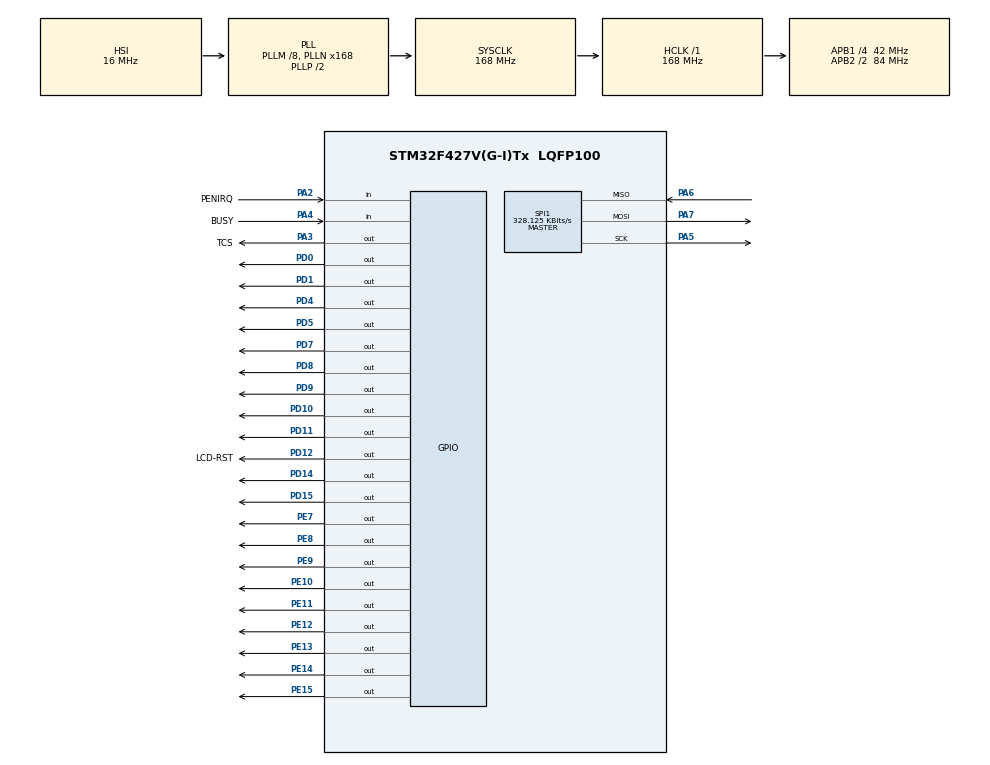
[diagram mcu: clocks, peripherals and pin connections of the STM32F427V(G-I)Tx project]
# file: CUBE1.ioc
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Mcu.Family=STM32F4
Mcu.Name=STM32F427V(G-I)Tx
Mcu.Package=LQFP100
NVIC.PriorityGroup=NVIC_PRIORITYGROUP_4
PA13.Mode=Serial_Wire
PA13.Signal=SYS_JTMS-SWDIO
PA14.Mode=Serial_Wire
PA14.Signal=SYS_JTCK-SWCLK
PA2.GPIO_Label=PENIRQ
PA2.GPIO_PuPd=GPIO_PULLUP
PA2.Signal=GPIO_Input
PA3.GPIO_Label=TCS
PA3.GPIO_PuPd=GPIO_PULLUP
PA3.GPIO_Speed=GPIO_SPEED_FREQ_HIGH
PA3.PinState=GPIO_PIN_SET
PA3.Signal=GPIO_Output
PA4.GPIO_Label=BUSY
PA4.GPIO_PuPd=GPIO_PULLUP
PA4.Signal=GPIO_Input
PA5.GPIO_PuPd=GPIO_PULLUP
PA5.GPIO_Speed=GPIO_SPEED_FREQ_HIGH
PA5.Mode=Full_Duplex_Master
PA5.Signal=SPI1_SCK
PA6.GPIO_PuPd=GPIO_PULLUP
PA6.GPIO_Speed=GPIO_SPEED_FREQ_HIGH
PA6.Mode=Full_Duplex_Master
PA6.Signal=SPI1_MISO
PA7.GPIO_PuPd=GPIO_PULLUP
PA7.GPIO_Speed=GPIO_SPEED_FREQ_HIGH
PA7.Mode=Full_Duplex_Master
PA7.Signal=SPI1_MOSI
PD0.GPIO_ModeDefaultOutputPP=GPIO_MODE_OUTPUT_PP
PD0.GPIO_PuPd=GPIO_PULLUP
PD0.GPIO_Speed=GPIO_SPEED_FREQ_HIGH
PD0.PinState=GPIO_PIN_SET
PD0.Signal=GPIO_Output
PD1.GPIO_ModeDefaultOutputPP=GPIO_MODE_OUTPUT_PP
PD1.GPIO_PuPd=GPIO_PULLUP
PD1.GPIO_Speed=GPIO_SPEED_FREQ_HIGH
PD1.PinState=GPIO_PIN_SET
PD1.Signal=GPIO_Output
PD10.GPIO_ModeDefaultOutputPP=GPIO_MODE_OUTPUT_PP
PD10.GPIO_PuPd=GPIO_PULLUP
PD10.GPIO_Speed=GPIO_SPEED_FREQ_HIGH
PD10.PinState=GPIO_PIN_SET
PD10.Signal=GPIO_Output
PD11.GPIO_ModeDefaultOutputPP=GPIO_MODE_OUTPUT_PP
PD11.GPIO_PuPd=GPIO_PULLUP
PD11.GPIO_Speed=GPIO_SPEED_FREQ_HIGH
PD11.PinState=GPIO_PIN_SET
PD11.Signal=GPIO_Output
PD12.GPIO_Label=LCD-RST
PD12.GPIO_ModeDefaultOutputPP=GPIO_MODE_OUTPUT_PP
PD12.GPIO_PuPd=GPIO_PULLUP
PD12.GPIO_Speed=GPIO_SPEED_FREQ_HIGH
PD12.PinState=GPIO_PIN_SET
PD12.Signal=GPIO_Output
PD14.GPIO_ModeDefaultOutputPP=GPIO_MODE_OUTPUT_PP
PD14.GPIO_PuPd=GPIO_PULLUP
PD14.GPIO_Speed=GPIO_SPEED_FREQ_HIGH
PD14.PinState=GPIO_PIN_SET
PD14.Signal=GPIO_Output
PD15.GPIO_ModeDefaultOutputPP=GPIO_MODE_OUTPUT_PP
PD15.GPIO_PuPd=GPIO_PULLUP
PD15.GPIO_Speed=GPIO_SPEED_FREQ_HIGH
PD15.PinState=GPIO_PIN_SET
PD15.Signal=GPIO_Output
PD4.GPIO_ModeDefaultOutputPP=GPIO_MODE_OUTPUT_PP
PD4.GPIO_PuPd=GPIO_PULLUP
PD4.GPIO_Speed=GPIO_SPEED_FREQ_HIGH
PD4.PinState=GPIO_PIN_SET
PD4.Signal=GPIO_Output
PD5.GPIO_ModeDefaultOutputPP=GPIO_MODE_OUTPUT_PP
PD5.GPIO_PuPd=GPIO_PULLUP
PD5.GPIO_Speed=GPIO_SPEED_FREQ_HIGH
PD5.PinState=GPIO_PIN_SET
PD5.Signal=GPIO_Output
PD7.GPIO_ModeDefaultOutputPP=GPIO_MODE_OUTPUT_PP
PD7.GPIO_PuPd=GPIO_PULLUP
PD7.GPIO_Speed=GPIO_SPEED_FREQ_HIGH
PD7.PinState=GPIO_PIN_SET
PD7.Signal=GPIO_Output
PD8.GPIO_ModeDefaultOutputPP=GPIO_MODE_OUTPUT_PP
PD8.GPIO_PuPd=GPIO_PULLUP
PD8.GPIO_Speed=GPIO_SPEED_FREQ_HIGH
PD8.PinState=GPIO_PIN_SET
PD8.Signal=GPIO_Output
PD9.GPIO_ModeDefaultOutputPP=GPIO_MODE_OUTPUT_PP
PD9.GPIO_PuPd=GPIO_PULLUP
PD9.GPIO_Speed=GPIO_SPEED_FREQ_HIGH
PD9.PinState=GPIO_PIN_SET
PD9.Signal=GPIO_Output
PE10.GPIO_ModeDefaultOutputPP=GPIO_MODE_OUTPUT_PP
PE10.GPIO_PuPd=GPIO_PULLUP
PE10.GPIO_Speed=GPIO_SPEED_FREQ_HIGH
PE10.PinState=GPIO_PIN_SET
PE10.Signal=GPIO_Output
PE11.GPIO_ModeDefaultOutputPP=GPIO_MODE_OUTPUT_PP
PE11.GPIO_PuPd=GPIO_PULLUP
PE11.GPIO_Speed=GPIO_SPEED_FREQ_HIGH
PE11.PinState=GPIO_PIN_SET
PE11.Signal=GPIO_Output
PE12.GPIO_ModeDefaultOutputPP=GPIO_MODE_OUTPUT_PP
PE12.GPIO_PuPd=GPIO_PULLUP
PE12.GPIO_Speed=GPIO_SPEED_FREQ_HIGH
PE12.PinState=GPIO_PIN_SET
PE12.Signal=GPIO_Output
PE13.GPIO_ModeDefaultOutputPP=GPIO_MODE_OUTPUT_PP
PE13.GPIO_PuPd=GPIO_PULLUP
PE13.GPIO_Speed=GPIO_SPEED_FREQ_HIGH
PE13.PinState=GPIO_PIN_SET
PE13.Signal=GPIO_Output
PE14.GPIO_ModeDefaultOutputPP=GPIO_MODE_OUTPUT_PP
PE14.GPIO_PuPd=GPIO_PULLUP
PE14.GPIO_Speed=GPIO_SPEED_FREQ_HIGH
PE14.PinState=GPIO_PIN_SET
PE14.Signal=GPIO_Output
PE15.GPIO_ModeDefaultOutputPP=GPIO_MODE_OUTPUT_PP
PE15.GPIO_PuPd=GPIO_PULLUP
PE15.GPIO_Speed=GPIO_SPEED_FREQ_HIGH
PE15.PinState=GPIO_PIN_SET
PE15.Signal=GPIO_Output
PE7.GPIO_ModeDefaultOutputPP=GPIO_MODE_OUTPUT_PP
PE7.GPIO_PuPd=GPIO_PULLUP
PE7.GPIO_Speed=GPIO_SPEED_FREQ_HIGH
PE7.PinState=GPIO_PIN_SET
PE7.Signal=GPIO_Output
PE8.GPIO_ModeDefaultOutputPP=GPIO_MODE_OUTPUT_PP
PE8.GPIO_PuPd=GPIO_PULLUP
PE8.GPIO_Speed=GPIO_SPEED_FREQ_HIGH
PE8.PinState=GPIO_PIN_SET
PE8.Signal=GPIO_Output
PE9.GPIO_ModeDefaultOutputPP=GPIO_MODE_OUTPUT_PP
PE9.GPIO_PuPd=GPIO_PULLUP
PE9.GPIO_Speed=GPIO_SPEED_FREQ_HIGH
PE9.PinState=GPIO_PIN_SET
PE9.Signal=GPIO_Output
ProjectManager.HeapSize=0x200
ProjectManager.StackSize=0x400
ProjectManager.TargetToolchain=Other Toolchains (GPDSC)
RCC.48MHZClocksFreq_Value=84000000
RCC.AHBFreq_Value=168000000
RCC.APB1CLKDivider=RCC_HCLK_DIV4
RCC.APB1Freq_Value=42000000
RCC.APB1TimFreq_Value=84000000
RCC.APB2CLKDivider=RCC_HCLK_DIV2
RCC.APB2Freq_Value=84000000
RCC.APB2TimFreq_Value=168000000
RCC.CortexFreq_Value=168000000
RCC.HCLKFreq_Value=168000000
RCC.HSE_VALUE=25000000
RCC.HSI_VALUE=16000000
RCC.LSE_VALUE=32768
RCC.PLLM=8
RCC.PLLN=168
RCC.SYSCLKFreq_VALUE=168000000
RCC.SYSCLKSource=RCC_SYSCLKSOURCE_PLLCLK
RCC.VCOOutputFreq_Value=336000000
SPI1.BaudRatePrescaler=SPI_BAUDRATEPRESCALER_256
SPI1.CLKPhase=SPI_PHASE_2EDGE
SPI1.CLKPolarity=SPI_POLARITY_HIGH
SPI1.CRCCalculation=SPI_CRCCALCULATION_DISABLE
SPI1.CalculateBaudRate=328.125 KBits/s
SPI1.DataSize=SPI_DATASIZE_8BIT
SPI1.Direction=SPI_DIRECTION_2LINES
SPI1.FirstBit=SPI_FIRSTBIT_MSB
SPI1.Mode=SPI_MODE_MASTER
SPI1.VirtualType=VM_MASTER
VP_CRC_VS_CRC.Mode=CRC_Activate
board=custom

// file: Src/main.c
/* USER CODE BEGIN Header */
/**
  ******************************************************************************
  * @file           : main.c
  * @brief          : Main program body
  ******************************************************************************
  * @attention
  *
  * <h2><center>&copy; Copyright (c) 2020 STMicroelectronics.
  * All rights reserved.</center></h2>
  *
  * This software component is licensed by ST under BSD 3-Clause license,
  * the "License"; You may not use this file except in compliance with the
  * License. You may obtain a copy of the License at:
  *                        opensource.org/licenses/BSD-3-Clause
  *
  ******************************************************************************
  */
/* USER CODE END Header */

#include "main.h"

/* USER CODE BEGIN Includes */
#include "GUI.h"
#include "HX8352B-F4-PAR.h"
#include "WindowDLG.h"
#include "GUITDRV_ADS7846.h"
#include "XPT2046-REZ.h"
/* USER CODE END Includes */

CRC_HandleTypeDef hcrc;

SPI_HandleTypeDef hspi1;

/* USER CODE BEGIN PV */
uint8_t		TDATA[3], BUSY, TCMD[6];
uint16_t	Result, TCSDATA[4];
/* USER CODE END PV */

void SystemClock_Config(void);
static void MX_GPIO_Init(void);
static void MX_CRC_Init(void);
static void MX_SPI1_Init(void);

int main(void)
{

  /* MCU Configuration--------------------------------------------------------*/

  /* Reset of all peripherals, Initializes the Flash interface and the Systick. */
  HAL_Init();

  /* Configure the system clock */
  SystemClock_Config();

  /* Initialize all configured peripherals */
  MX_GPIO_Init();
  MX_CRC_Init();
  MX_SPI1_Init();
  /* USER CODE BEGIN 2 */
	GUI_Init();
	//GUI_SetFont(&GUI_Font32B_1);
	//GUI_SetBkColor(GUI_BLUE);
	//GUI_SetColor(GUI_BLACK);
	//GUI_SetLineStyle(GUI_LS_DASHDOTDOT);
	//GUI_CURSOR_Select(&GUI_CursorArrowM);
	//GUI_CURSOR_SetPosition(10, 150);
	//GUI_Clear();
	//GUI_SetLineStyle(GUI_LS_SOLID);
	//LCD_RECT GUI_RECT = { 0 };
	//GUI_RECT.x0 = 70;
	//GUI_RECT.x1 = 350;
	//GUI_RECT.y0 = 70;
	//GUI_RECT.y1 = 160;

	//GUI_DrawRect(60, 60, 350, 160);

	//GUI_DispStringInRect("Hello.........World!", &GUI_RECT, GUI_TA_HCENTER);

	//GUI_CURSOR_SetPosition(20, 50);
	//GUI_CURSOR_Show();

	//
	MainTask();  // CreateWindow();

  /* USER CODE END 2 */

  /* Infinite loop */
  while(1)
	{

    /* USER CODE BEGIN 3 */

		//CreateWindow();
		HAL_Delay(100);

		/*

		SendCmd(0XD0);
		TCSDATA[3] = GetResult();
		SetCS(1);

		HAL_Delay(100);

			TOUCH_X_Init				// S / A2 A1 A0 / MODE / SER_DFR / PD1 PD0
		TCMD[0] = 0X90;   //1 / 101        / 1   / 0        / 00       X-POSITION
		TCMD[1] = 0X00;   //1 / 001        / 1   / 0        / 00       Y-POSITION
		TCMD[2] = 0X00;

		TCMD[3] = 0XD0;
		TCMD[4] = 0X00;
		TCMD[5] = 0X00;

		//YY :if (HAL_GPIO_ReadPin(GPIOA, PENIRQ_Pin)) {goto YY; }	else

		HAL_GPIO_WritePin(GPIOA, TCS_Pin, GPIO_PIN_RESET);
		HAL_Delay(1);

		HAL_SPI_TransmitReceive(&hspi1, &TCMD[0], &TDATA[0], 1, 15);
		HAL_SPI_TransmitReceive(&hspi1, &TCMD[1], &TDATA[1], 2, 15);
		TCSDATA[3] = ((TDATA[1] << 4) | (TDATA[2] >> 4)) & 0X0FFF;

		HAL_SPI_TransmitReceive(&hspi1, &TCMD[3], &TDATA[0], 1, 15);
		HAL_SPI_TransmitReceive(&hspi1, &TCMD[4], &TDATA[1], 2, 15);
		TCSDATA[2] = ((TDATA[1] << 4) | (TDATA[2] >> 4)) & 0X0FFF;

		HAL_GPIO_WritePin(GPIOA, TCS_Pin, GPIO_PIN_SET);

							// S / A2 A1 A0 / MODE / SER_DFR / PD1 PD0
		TCMD[0] = 0XD0;   //1 / 101        / 1   / 0        / 00       X-POSITION
		TCMD[1] = 0X90;   //1 / 001        / 1   / 0        / 00       Y-POSITION
		TCMD[2] = 0X00;

		HAL_SPI_TransmitReceive(&hspi1, &TCMD[0], &TDATA[0], 1, 5);
		HAL_SPI_TransmitReceive(&hspi1, &TCMD[2], &TDATA[1], 1, 5);
		TCSDATA[0] = TDATA[0];
		TCSDATA[1] = TDATA[1];
		TCSDATA[3] = ((TCSDATA[0] << 4) | (TCSDATA[1] >> 4)) & 0X0FFF;

		 	XX:
		if (HAL_GPIO_ReadPin(GPIOA, BUSY_Pin) == 0)
		{
			HAL_SPI_Receive(&hspi1, &TDATA[0], 1, 25);
			HAL_SPI_Receive(&hspi1, &TDATA[1], 1, 25);
			TCSDATA = (TDATA[0] << 4 | TDATA[1]>>4) & 0X0FFF;
		}
		else goto XX;

		HAL_SPI_Transmit(&hspi1, &TCMD[1], 1, 5);
		YY :
		if (HAL_GPIO_ReadPin(GPIOA, BUSY_Pin) == 0)
		{}		else goto YY;

			HAL_Delay(40);
		GUITDRV_ADS7846_Exec();
		HAL_Delay(40);

		 HAL_Delay(10);
		GUI_DispStringAt("Hello.........World!", 50, 10);
		HAL_Delay(10);
		GUI_DispStringAt("Hello.........World!", 50, 50);
		HAL_Delay(10);
		GUI_DispStringAt("Hello.........World!", 50, 100);
		HAL_Delay(10);
		GUI_DispStringAt("Hello.........World!!", 50, 150);
		HAL_Delay(10);
		GUI_DispStringAt("Hello.........World!!", 50, 200);
		HAL_Delay(10);
		GUI_Clear();
		HAL_Delay(10);
		//GUI_DrawRect(50, 50, 350, 160);
		//GUI_DispStringInRect("Hello.........World!", &GUI_RECT, GUI_TA_HCENTER);
		HAL_Delay(1000);
		GUI_Clear();

		 E1 = ((address << 3) & 0XFF80);
		 D1 = (address << 14) & 0XC000;
		 D2 = (address >> 2) & 0X0003;
		 D3 = (address >> 5) & 0X0700;
		 D4 = (D1 | D2 | D3) | 0X38FC;
		 GPIOE->ODR = E1;
		 GPIOD->ODR = D4;
		 HAL_Delay(20);
		 GPIOD->ODR = D4 & CS_MASK; 		//CS=LOW RS=HIGH WR=HIGH RD=HIGH
		 HAL_Delay(30);
		 GPIOD->ODR = D4 & (RS_MASK & CS_MASK);  		//CS=LOW RS=LOW WR=HIGH RD=HIGH
		 HAL_Delay(20);
		 GPIOD->ODR = D4 & (WR_MASK & RS_MASK & CS_MASK); 		//CS=LOW RS=LOW WR=LOW RD=HIGH
		 HAL_Delay(20);
		 GPIOD->ODR = (D4 & (RS_MASK & CS_MASK)) | (~WR_MASK);   	//CS=LOW RS=LOW WR=HIGH RD=HIGH
		 HAL_Delay(20);
		 GPIOD->ODR = (D4 & (CS_MASK)) | (~RS_MASK); 	//CS=LOW RS=HIGH WR=HIGH RD=HIGH
		 HAL_Delay(20);
		 */
	}
  /* USER CODE END 3 */
}

void SystemClock_Config(void)
{
  RCC_OscInitTypeDef RCC_OscInitStruct = {0};
  RCC_ClkInitTypeDef RCC_ClkInitStruct = {0};

  /** Configure the main internal regulator output voltage
  */
  __HAL_RCC_PWR_CLK_ENABLE();
  __HAL_PWR_VOLTAGESCALING_CONFIG(PWR_REGULATOR_VOLTAGE_SCALE1);
  /** Initializes the CPU, AHB and APB busses clocks
  */
  RCC_OscInitStruct.OscillatorType = RCC_OSCILLATORTYPE_HSI;
  RCC_OscInitStruct.HSIState = RCC_HSI_ON;
  RCC_OscInitStruct.HSICalibrationValue = RCC_HSICALIBRATION_DEFAULT;
  RCC_OscInitStruct.PLL.PLLState = RCC_PLL_ON;
  RCC_OscInitStruct.PLL.PLLSource = RCC_PLLSOURCE_HSI;
  RCC_OscInitStruct.PLL.PLLM = 8;
  RCC_OscInitStruct.PLL.PLLN = 168;
  RCC_OscInitStruct.PLL.PLLP = RCC_PLLP_DIV2;
  RCC_OscInitStruct.PLL.PLLQ = 4;
  if (HAL_RCC_OscConfig(&RCC_OscInitStruct) != HAL_OK)
  {
    Error_Handler();
  }
  /** Initializes the CPU, AHB and APB busses clocks
  */
  RCC_ClkInitStruct.ClockType = RCC_CLOCKTYPE_HCLK|RCC_CLOCKTYPE_SYSCLK
                              |RCC_CLOCKTYPE_PCLK1|RCC_CLOCKTYPE_PCLK2;
  RCC_ClkInitStruct.SYSCLKSource = RCC_SYSCLKSOURCE_PLLCLK;
  RCC_ClkInitStruct.AHBCLKDivider = RCC_SYSCLK_DIV1;
  RCC_ClkInitStruct.APB1CLKDivider = RCC_HCLK_DIV4;
  RCC_ClkInitStruct.APB2CLKDivider = RCC_HCLK_DIV2;

  if (HAL_RCC_ClockConfig(&RCC_ClkInitStruct, FLASH_LATENCY_5) != HAL_OK)
  {
    Error_Handler();
  }
}

static void MX_CRC_Init(void)
{

  hcrc.Instance = CRC;
  if (HAL_CRC_Init(&hcrc) != HAL_OK)
  {
    Error_Handler();
  }

}

static void MX_SPI1_Init(void)
{

  /* SPI1 parameter configuration*/
  hspi1.Instance = SPI1;
  hspi1.Init.Mode = SPI_MODE_MASTER;
  hspi1.Init.Direction = SPI_DIRECTION_2LINES;
  hspi1.Init.DataSize = SPI_DATASIZE_8BIT;
  hspi1.Init.CLKPolarity = SPI_POLARITY_HIGH;
  hspi1.Init.CLKPhase = SPI_PHASE_2EDGE;
  hspi1.Init.NSS = SPI_NSS_SOFT;
  hspi1.Init.BaudRatePrescaler = SPI_BAUDRATEPRESCALER_256;
  hspi1.Init.FirstBit = SPI_FIRSTBIT_MSB;
  hspi1.Init.TIMode = SPI_TIMODE_DISABLE;
  hspi1.Init.CRCCalculation = SPI_CRCCALCULATION_DISABLE;
  hspi1.Init.CRCPolynomial = 10;
  if (HAL_SPI_Init(&hspi1) != HAL_OK)
  {
    Error_Handler();
  }

}

static void MX_GPIO_Init(void)
{
  GPIO_InitTypeDef GPIO_InitStruct = {0};

  /* GPIO Ports Clock Enable */
  __HAL_RCC_GPIOA_CLK_ENABLE();
  __HAL_RCC_GPIOE_CLK_ENABLE();
  __HAL_RCC_GPIOD_CLK_ENABLE();

  /*Configure GPIO pin Output Level */
  HAL_GPIO_WritePin(TCS_GPIO_Port, TCS_Pin, GPIO_PIN_SET);

  /*Configure GPIO pin Output Level */
  HAL_GPIO_WritePin(GPIOE, GPIO_PIN_7|GPIO_PIN_8|GPIO_PIN_9|GPIO_PIN_10
                          |GPIO_PIN_11|GPIO_PIN_12|GPIO_PIN_13|GPIO_PIN_14
                          |GPIO_PIN_15, GPIO_PIN_SET);

  /*Configure GPIO pin Output Level */
  HAL_GPIO_WritePin(GPIOD, GPIO_PIN_8|GPIO_PIN_9|GPIO_PIN_10|GPIO_PIN_11
                          |LCD_RST_Pin|GPIO_PIN_14|GPIO_PIN_15|GPIO_PIN_0
                          |GPIO_PIN_1|GPIO_PIN_4|GPIO_PIN_5|GPIO_PIN_7, GPIO_PIN_SET);

  /*Configure GPIO pins : PENIRQ_Pin BUSY_Pin */
  GPIO_InitStruct.Pin = PENIRQ_Pin|BUSY_Pin;
  GPIO_InitStruct.Mode = GPIO_MODE_INPUT;
  GPIO_InitStruct.Pull = GPIO_PULLUP;
  HAL_GPIO_Init(GPIOA, &GPIO_InitStruct);

  /*Configure GPIO pin : TCS_Pin */
  GPIO_InitStruct.Pin = TCS_Pin;
  GPIO_InitStruct.Mode = GPIO_MODE_OUTPUT_PP;
  GPIO_InitStruct.Pull = GPIO_PULLUP;
  GPIO_InitStruct.Speed = GPIO_SPEED_FREQ_HIGH;
  HAL_GPIO_Init(TCS_GPIO_Port, &GPIO_InitStruct);

  /*Configure GPIO pins : PE7 PE8 PE9 PE10
                           PE11 PE12 PE13 PE14
                           PE15 */
  GPIO_InitStruct.Pin = GPIO_PIN_7|GPIO_PIN_8|GPIO_PIN_9|GPIO_PIN_10
                          |GPIO_PIN_11|GPIO_PIN_12|GPIO_PIN_13|GPIO_PIN_14
                          |GPIO_PIN_15;
  GPIO_InitStruct.Mode = GPIO_MODE_OUTPUT_PP;
  GPIO_InitStruct.Pull = GPIO_PULLUP;
  GPIO_InitStruct.Speed = GPIO_SPEED_FREQ_HIGH;
  HAL_GPIO_Init(GPIOE, &GPIO_InitStruct);

  /*Configure GPIO pins : PD8 PD9 PD10 PD11
                           LCD_RST_Pin PD14 PD15 PD0
                           PD1 PD4 PD5 PD7 */
  GPIO_InitStruct.Pin = GPIO_PIN_8|GPIO_PIN_9|GPIO_PIN_10|GPIO_PIN_11
                          |LCD_RST_Pin|GPIO_PIN_14|GPIO_PIN_15|GPIO_PIN_0
                          |GPIO_PIN_1|GPIO_PIN_4|GPIO_PIN_5|GPIO_PIN_7;
  GPIO_InitStruct.Mode = GPIO_MODE_OUTPUT_PP;
  GPIO_InitStruct.Pull = GPIO_PULLUP;
  GPIO_InitStruct.Speed = GPIO_SPEED_FREQ_HIGH;
  HAL_GPIO_Init(GPIOD, &GPIO_InitStruct);

}

void Error_Handler(void)
{
}

/************************ (C) COPYRIGHT STMicroelectronics *****END OF FILE****/
